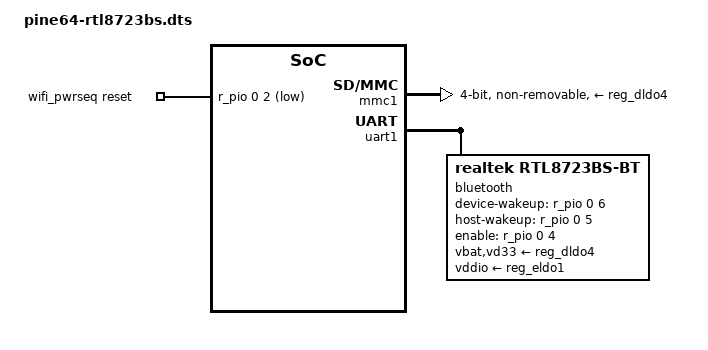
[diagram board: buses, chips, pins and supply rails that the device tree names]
// SPDX-License-Identifier: (GPL-2.0+ OR MIT)
//
// Copyright (C) 2018 Chen-Yu Tsai <wens@csie.org>
//
// RTL8723BS module attached on WiFi connector

#ifdef __DTO_TEST__
#include <arm64/allwinner/sun50i-a64-pine64.dts>
#else
/dts-v1/;
/plugin/;
#endif

#include <dt-bindings/gpio/gpio.h>

&{/} {
	wifi_pwrseq: wifi-pwrseq {
		compatible = "mmc-pwrseq-simple";
		reset-gpios = <&r_pio 0 2 GPIO_ACTIVE_LOW>; /* PL2 WIFI_EN */
	};
};

&mmc1 {
	pinctrl-names = "default";
	pinctrl-0 = <&mmc1_pins>;
	vmmc-supply = <&reg_dldo4>;
	vqmmc-supply = <&reg_eldo1>;
	mmc-pwrseq = <&wifi_pwrseq>;
	bus-width = <4>;
	non-removable;
	status = "okay";
};

&uart1 {
	pinctrl-names = "default";
	pinctrl-0 = <&uart1_pins>;
	status = "okay";

	bluetooth {
		compatible = "realtek,rtl8723bs-bt";
		vbat-supply = <&reg_dldo4>;
		vd33-supply = <&reg_dldo4>;
		vddio-supply = <&reg_eldo1>;
		device-wakeup-gpios = <&r_pio 0 6 GPIO_ACTIVE_HIGH>; /* PL6 */
		host-wakeup-gpios = <&r_pio 0 5 GPIO_ACTIVE_HIGH>; /* PL5 */
		enable-gpios = <&r_pio 0 4 GPIO_ACTIVE_HIGH>; /* PL4 */
	};
};
